# YTM32B1HA0 register map
Vendor: YTMicro; File version: 1.0
CPU: little endian, MPU, FPU, 2 interrupt priority bits
Registers are 32-bit, read-write, reset 0x0 unless marked. A register's access mark holds for its fields unless they carry their own. Offsets are from the block's base; [hi:lo] are bit positions; {n}, {i} and the like mark numbered series.

## MPWM0
Base 0x40144000; register names take the prefix MPWM0_
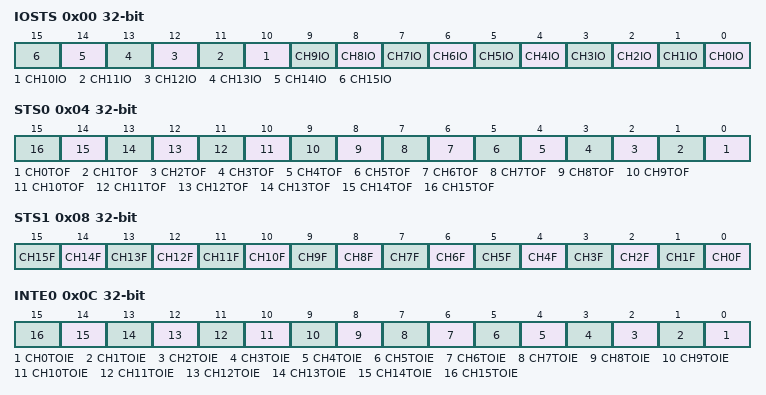
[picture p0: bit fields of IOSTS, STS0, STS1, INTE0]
0x00 IOSTS
  [all] fields
    0=Channel status is 0; 1=Channel status is 1
  [n] CH{n}IO ro (n=0..15) — Indicate channel {n} input/output status in pwm mode, compare mode and input capture mode. This bit is read only and the write operation is invalid.
0x04 STS0
  [all] fields
    0=No timer overflow event occurs; 1=Timer overflow event occurs
  [n] CH{n}TOF (n=0..15) — Indicate channel {n} timer overflow flag. Write 1 to clear the bit.
0x08 STS1
  [all] fields
    0=No channel event occurs; 1=Channel event occurs
  [n] CH{n}F (n=0..15) — Indicate channel {n} matching event flag in pwm mode and compare mode. Indicate channel 15 capture event flag in input capture mode. Write 1 to clear the bit.
0x0C INTE0
  [n] CH{n}TOIE (n=0..15) — Channel {n} timer overflow interrupt enable/disable.
    0=Channel {n} timer overflow interrupt is disabled; 1=Channel {n} timer overflow interrupt is enabled
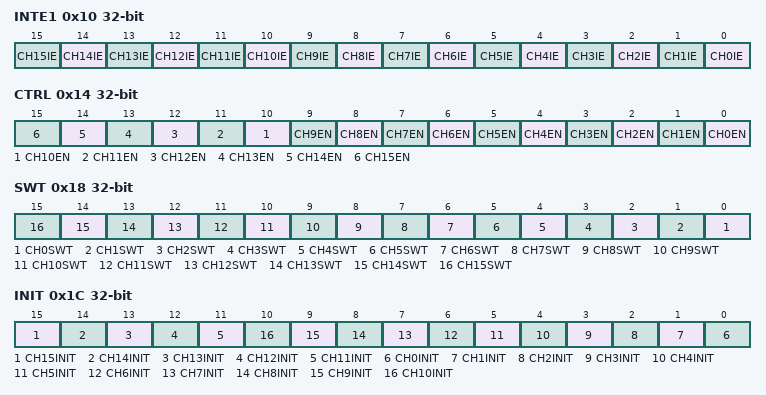
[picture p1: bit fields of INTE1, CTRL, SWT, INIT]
0x10 INTE1
  [n] CH{n}IE (n=0..15) — Channel {n} interrupt enable/disable.
    0=Channel {n} interrupt is disabled; 1=Channel {n} interrupt is enabled
0x14 CTRL
  [n] CH{n}EN (n=0..15) — Channel {n} enable/disable.
    0=Channel {n} is disabled; 1=Channel {n} is enabled
0x18 SWT
  [n] CH{n}SWT (n=0..15) — Channel {n} software trigger by writing 1 to this bit and keep a bus clock cycle. The bit is write only. Read operation is invalid and always returns 0.
0x1C INIT
  [15] CH15INIT — Channel 15 initial value in PWM mode and compare mode before Channel 15 is enabled.
    0=Channel 15 initial value is 0; 1=Channel 15 initial value is 1
  [14] CH14INIT — Channel 14 initial value in PWM mode and compare mode before Channel 14 is enabled.
    0=Channel 14 initial value is 0; 1=Channel 14 initial value is 1
  [13] CH13INIT — Channel 13 initial value in PWM mode and compare mode before Channel 13 is enabled.
    0=Channel 13 initial value is 0; 1=Channel 13 initial value is 1
  [12] CH12INIT — Channel 12 initial value in PWM mode and compare mode before Channel 12 is enabled.
    0=Channel initial value is 0; 1=Channel 12 initial value is 1
  [11] CH11INIT — Channel 11 initial value in PWM mode and compare mode before Channel 11 is enabled.
    0=Channel initial value is 0; 1=Channel 11 initial value is 1
  [n] CH{n}INIT (n=0..10) — Channel {n} initial value in PWM mode and compare mode before Channel {n} is enabled.
    0=Channel {n} initial value is 0; 1=Channel {n} initial value is 1
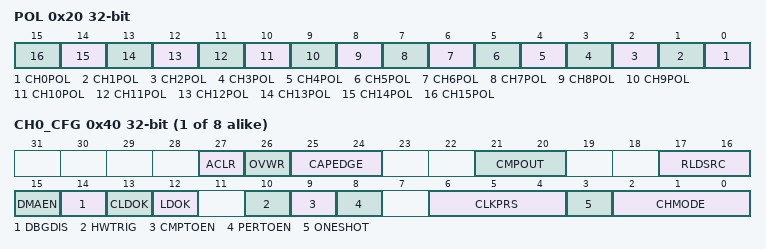
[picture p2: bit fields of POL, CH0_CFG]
0x20 POL
  [n] CH{n}POL (n=0..15) — Channel {n} polarity in PWM mode and compare mode.
    0=Not invert the channel {n} output; 1=Invert the channel {n} output
{0x40+0x20*i} CH{i}_CFG (i=0..7)
  [27] ACLR — Counter is automatically reset to 0 when capture event occurs.
    0=Auto clear is disabled; 1=Auto clear is enabled
  [26] OVWR — Over write the CAP register from counter when new capture event occurs.
    0=Over write is disabled; 1=Over write is enabled
  [25:24] CAPEDGE — Select the capture edge in the input capture mode.
    0=Capture is disabled; 1=Capture rising edge; 2=Capture falling edge; 3=Capture both rising edge and falling edge
  [21:20] CMPOUT — Select the output value when counter matches with CMP in compare mode.
    0=Compare Output disabled; 1=Output value 0; 2=Output value 1; 3=Output value toggle
  [17:16] RLDSRC — Double Buffer Registers reloading sources.
    0=PERIOD matching point reload; 1=Hardware trigger point reload; 2=Software trigger point reload; 3=Double buffer mechanism is disabled
  [15] DMAEN — When DMA is enabled and STS1[CHxF] is set, generate a DMA request.
    0=DMA request is disabled; 1=DMA request is enabled
  [14] DBGDIS — Enable/disable the debug mode.
    0=Counter stops under debug mode; 1=Counter keeps running under debug mode
  [13] CLDOK — Write 1 to this bit to clear CH_CFG[LDOK], and it automatically clear when CH_CFG[LDOK]=0.
  [12] LDOK — Set LDOK to indicate registers(CMP and PERIOD) is ready for loading, it is cleared automatically when registers load successfully.
    0=Registers is not ready for loading; 1=Registers is ready for loading and wait for loading opportunity
  [10] HWTRIG — Hardware trigger enable/disable.
    0=Hardware trigger is disabled; 1=Hardware trigger is enabled
  [9] CMPTOEN — Registers CMP matching trigger output enable/disable.
    0=Registers CMP matching trigger output is disabled; 1=Registers CMP matching trigger output is enabled
  [8] PERTOEN — Registers PERIOD matching trigger output enable/disable.
    0=Registers PERIOD matching trigger output is disabled; 1=Registers PERIOD matching trigger output is enabled
  [6:4] CLKPRS — Clock prescaler for counter.
    0=Divide by 1; 1=Divide by 2; 2=Divide by 4; 3=Divide by 8; 4=Divide by 16; 5=Divide by 32; 6=Divide by 64; 7=Divide by 128
  [3] ONESHOT — Counter counting mode.
    0=Continuous mode; 1=One shot mode
  [2:0] CHMODE — Channel mode.
    0=Common timer; 1=PWM mode; 2=Output compare mode; 3=Input capture mode; 4=Pulse counter mode
{0x44+0x20*i} CH{i}_CNT ro (i=0..7)
  [15:0] CNT rw — Reading this register gets the counter value, and writing to this register is invalid.
{0x48+0x20*i} CH{i}_CAP (i=0..7)
  [15:0] CAP — In capture mode, store counter value when a capture event occurs.
{0x50+0x20*i} CH{i}_PERIOD (i=0..7)
  [15:0] PERIOD — Counter counting period.
{0x54+0x20*i} CH{i}_CMP (i=0..7)
  [15:0] CMP — Counter compare value.

## MPWM1
Base 0x40148000; register names take the prefix MPWM1_
Registers as MPWM0.

## MPWM2
Base 0x4014C000; register names take the prefix MPWM2_
Registers as MPWM0.
